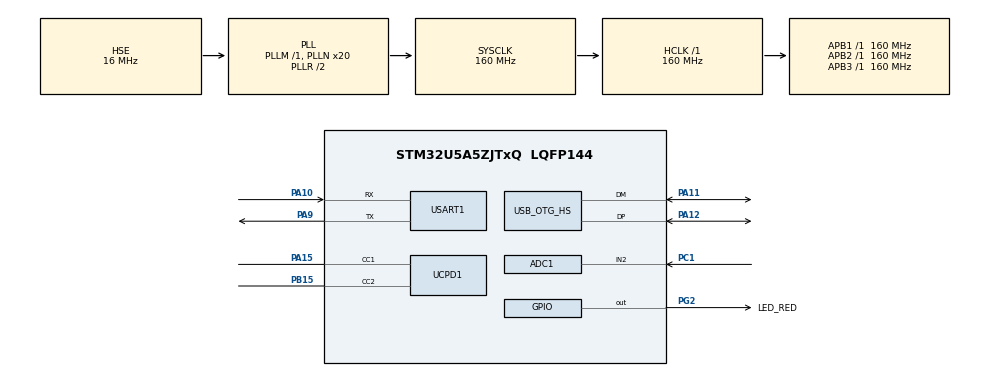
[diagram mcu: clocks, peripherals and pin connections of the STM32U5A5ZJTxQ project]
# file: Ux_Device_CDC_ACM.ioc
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ADC1.Channel-1\#ChannelRegularConversion=ADC_CHANNEL_2
ADC1.MonitoredBy-1\#ChannelRegularConversion=__NULL
ADC1.NbrOfConversionFlag=1
ADC1.OffsetNumber-1\#ChannelRegularConversion=ADC_OFFSET_NONE
ADC1.Rank-1\#ChannelRegularConversion=1
ADC1.SamplingTime-1\#ChannelRegularConversion=ADC_SAMPLETIME_5CYCLE
ADC1.master=1
CORTEX_M33_NS.userName=CORTEX_M33
GPDMA1.DIRECTION_GPDMACH0=DMA_MEMORY_TO_PERIPH
GPDMA1.DIRECTION_GPDMACH3=DMA_MEMORY_TO_PERIPH
GPDMA1.IPHANDLE_GPDMACH0-SIMPLEREQUEST_GPDMACH0=__NULL
GPDMA1.IPHANDLE_GPDMACH3-SIMPLEREQUEST_GPDMACH3=__NULL
GPDMA1.IPHANDLE_GPDMACH5-SIMPLEREQUEST_GPDMACH5=__NULL
GPDMA1.REQUEST_GPDMACH0=GPDMA1_REQUEST_USART1_TX
GPDMA1.REQUEST_GPDMACH3=GPDMA1_REQUEST_UCPD1_TX
GPDMA1.REQUEST_GPDMACH5=GPDMA1_REQUEST_UCPD1_RX
GPDMA1.SRCINC_GPDMACH0=DMA_SINC_INCREMENTED
Mcu.Family=STM32U5
Mcu.Name=STM32U5A5ZJTxQ
Mcu.Package=LQFP144
NVIC.GPDMA1_Channel0_IRQn=true\:0\:0\:false\:false\:true\:true\:true\:true\:true
NVIC.GPDMA1_Channel3_IRQn=true\:0\:0\:false\:false\:true\:true\:true\:true\:true
NVIC.GPDMA1_Channel5_IRQn=true\:0\:0\:false\:false\:true\:true\:true\:true\:true
NVIC.OTG_HS_IRQn=true\:7\:0\:true\:false\:true\:false\:true\:true\:true
NVIC.PriorityGroup=NVIC_PRIORITYGROUP_4
NVIC.TIM6_IRQn=true\:15\:0\:false\:false\:true\:false\:false\:true\:true
NVIC.TimeBase=TIM6_IRQn
NVIC.TimeBaseIP=TIM6
NVIC.UCPD1_IRQn=true\:5\:0\:true\:false\:true\:false\:true\:false\:true
NVIC.USART1_IRQn=true\:6\:0\:true\:false\:true\:false\:true\:true\:true
PA10.GPIO_PuPd=GPIO_PULLUP
PA10.GPIO_Speed=GPIO_SPEED_FREQ_HIGH
PA10.Mode=Asynchronous
PA10.Signal=USART1_RX
PA11.GPIO_Speed=GPIO_SPEED_FREQ_LOW
PA11.Mode=Internal_Phy_Device
PA11.Signal=USB_OTG_HS_DM
PA12.GPIO_Speed=GPIO_SPEED_FREQ_LOW
PA12.Mode=Internal_Phy_Device
PA12.Signal=USB_OTG_HS_DP
PA15\ (JTDI).Mode=Sink_AllSignals
PA15\ (JTDI).Signal=UCPD1_CC1
PA9.GPIO_PuPd=GPIO_PULLUP
PA9.GPIO_Speed=GPIO_SPEED_FREQ_HIGH
PA9.Mode=Asynchronous
PA9.Signal=USART1_TX
PB15.Mode=Sink_AllSignals
PB15.Signal=UCPD1_CC2
PC1.Mode=IN2-Single-Ended
PC1.Signal=ADC1_IN2
PG2.GPIO_Label=LED_RED
PG2.Signal=GPIO_Output
PH0-OSC_IN\ (PH0).Mode=HSE-External-Oscillator
PH0-OSC_IN\ (PH0).Signal=RCC_OSC_IN
PH1-OSC_OUT\ (PH1).Mode=HSE-External-Oscillator
PH1-OSC_OUT\ (PH1).Signal=RCC_OSC_OUT
PWR.PowerMode=PWR_SMPS_SUPPLY
ProjectManager.HeapSize=0x200
ProjectManager.StackSize=0x400
ProjectManager.TargetToolchain=EWARM V8.50
RCC.ADCFreq_Value=16000000
RCC.AHBFreq_Value=160000000
RCC.APB1Freq_Value=160000000
RCC.APB1TimFreq_Value=160000000
RCC.APB2Freq_Value=160000000
RCC.APB2TimFreq_Value=160000000
RCC.APB3Freq_Value=160000000
RCC.CortexFreq_Value=160000000
RCC.DACCLockSelectionVirtual=RCC_DAC1CLKSOURCE_LSI
RCC.EPOD_VALUE=16000000
RCC.HCLKFreq_Value=160000000
RCC.HSE_VALUE=16000000
RCC.HSI48_VALUE=48000000
RCC.HSI_VALUE=16000000
RCC.LSE_VALUE=32768
RCC.LSIDIV_VALUE=32000
RCC.MSIClockRange=RCC_MSIRANGE_0
RCC.MSI_VALUE=48000000
RCC.PLL1P=8
RCC.PLL2FRACN=0
RCC.PLL3FRACN=0
RCC.PLLFRACN=0
RCC.PLLN=20
RCC.PLLSourceVirtual=RCC_PLLSOURCE_HSE
RCC.SYSCLKFreq_VALUE=160000000
RCC.SYSCLKSource=RCC_SYSCLKSOURCE_PLLCLK
RCC.USBPHYCLockSelection=RCC_USBPHYCLKSOURCE_HSE
RCC.VCOOutputFreq_Value=320000000
USART1.VirtualMode-Asynchronous=VM_ASYNC
USBX.BSP.number=1
USBX.Core_System=1
USBX.MAX_POWER_IN_MILLI_AMPER=0
USBX.USBD_CDCACM_EPINCMD_ADDR=2
USBX.USBD_CDCACM_EPIN_ADDR=1
USBX.USBD_CDCACM_EPIN_HS_MPS=512
USBX.USBD_CDCACM_EPOUT_HS_MPS=512
USBX.USBD_PID=22336
USBX.USBD_PRODUCT_STRING=STM32 Virtual ComPort
USBX.USBD_SERIAL_NUMBER=CDC_ACM001
USBX.USBX_DEVICE_SYS_SIZE=4*1024
USBX.UX_DEVICE_APP_MEM_POOL_SIZE=8192
USBX.UX_DEVICE_CDC_ACM=1
USBX.UX_Device_Controller=1
USBX.UX_Device_CoreStack=1
USBX.UX_SLAVE_REQUEST_CONTROL_MAX_LENGTH=256
USBX.UX_SLAVE_REQUEST_DATA_MAX_LENGTH=512
USBX0.BSP.STBoard=false
USBX0.BSP.api=Unknown
USBX0.BSP.instance=USB_OTG_HS
USBX0.BSP.ip=USB_OTG_HS
USBX0.BSP.mode=Device_Only
USBX0.BSP.name=USBDevice
USBX0.BSP.solution=USB_OTG_HS
USB_OTG_HS.VirtualMode=Device_HS
VP_GPDMA1_VS_GPDMACH0.Mode=SIMPLEREQUEST_GPDMACH0
VP_GPDMA1_VS_GPDMACH3.Mode=SIMPLEREQUEST_GPDMACH3
VP_GPDMA1_VS_GPDMACH5.Mode=SIMPLEREQUEST_GPDMACH5
VP_ICACHE_VS_ICACHE.Mode=DirectMappedCache
VP_PWR_VS_DBSignals.Mode=DisableDeadBatterySignals
VP_PWR_VS_LPOM.Mode=PowerOptimisation
VP_PWR_VS_SECSignals.Mode=Security/Privilege
VP_SYS_VS_tim6.Mode=TIM6
VP_THREADX_VS_RTOSJjThreadXJjCoreJjDefault.Mode=Core_Default
VP_USBPD_VS_PD3TYPEC.Mode=PD3_TypeC
VP_USBPD_VS_USBPD1.Mode=USBPD_P0
VP_USBPD_VS_usbpd_tim2.Mode=TIM2
VP_USBPD_VS_usbpd_usb_cohabitation.Mode=Enable USB Support
VP_USBX_Core_System.Mode=Core_System
VP_USBX_UX\ Device\ CDC\ ACM\ Class_HS.Mode=UX_Device_class_CDC_ACM_HS
VP_USBX_UX\ Device\ Controller_HS.Mode=UX_Device_Controller_HS
VP_USBX_UX\ Device\ CoreStack_HS.Mode=UX_Device_CoreStack_HS
board=NUCLEO-U5A5ZJ-Q

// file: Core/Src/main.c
/* USER CODE BEGIN Header */
/**
  ******************************************************************************
  * @file           : main.c
  * @brief          : Main program body
  ******************************************************************************
  * @attention
  *
  * Copyright (c) 2021 STMicroelectronics.
  * All rights reserved.
  *
  * This software is licensed under terms that can be found in the LICENSE file
  * in the root directory of this software component.
  * If no LICENSE file comes with this software, it is provided AS-IS.
  *
  ******************************************************************************
  */
/* USER CODE END Header */
#include "app_threadx.h"
#include "main.h"
#include "usbpd.h"

 ADC_HandleTypeDef hadc1;

UART_HandleTypeDef huart1;
DMA_HandleTypeDef handle_GPDMA1_Channel0;

PCD_HandleTypeDef hpcd_USB_OTG_HS;

void SystemClock_Config(void);
static void SystemPower_Config(void);
static void MX_GPIO_Init(void);
static void MX_GPDMA1_Init(void);
static void MX_ICACHE_Init(void);
static void MX_UCPD1_Init(void);
static void MX_ADC1_Init(void);

int main(void)
{

  /* MCU Configuration--------------------------------------------------------*/

  /* Reset of all peripherals, Initializes the Flash interface and the Systick. */
  HAL_Init();

  /* Configure the system clock */
  SystemClock_Config();

  /* Configure the System Power */
  SystemPower_Config();

  /* Initialize all configured peripherals */
  MX_GPIO_Init();
  MX_GPDMA1_Init();
  MX_ICACHE_Init();
  MX_USART1_UART_Init();
  MX_UCPD1_Init();
  MX_ADC1_Init();
  /* Call PreOsInit function */
  USBPD_PreInitOs();

  MX_ThreadX_Init();

  /* We should never get here as control is now taken by the scheduler */

  /* Infinite loop */
  while (1)
  {

  }
}

void SystemClock_Config(void)
{
  RCC_OscInitTypeDef RCC_OscInitStruct = {0};
  RCC_ClkInitTypeDef RCC_ClkInitStruct = {0};

  /** Configure the main internal regulator output voltage
  */
  if (HAL_PWREx_ControlVoltageScaling(PWR_REGULATOR_VOLTAGE_SCALE1) != HAL_OK)
  {
    Error_Handler();
  }

  /** Initializes the CPU, AHB and APB buses clocks
  */
  RCC_OscInitStruct.OscillatorType = RCC_OSCILLATORTYPE_HSI|RCC_OSCILLATORTYPE_HSE;
  RCC_OscInitStruct.HSEState = RCC_HSE_ON;
  RCC_OscInitStruct.HSIState = RCC_HSI_ON;
  RCC_OscInitStruct.HSICalibrationValue = RCC_HSICALIBRATION_DEFAULT;
  RCC_OscInitStruct.PLL.PLLState = RCC_PLL_ON;
  RCC_OscInitStruct.PLL.PLLSource = RCC_PLLSOURCE_HSE;
  RCC_OscInitStruct.PLL.PLLMBOOST = RCC_PLLMBOOST_DIV1;
  RCC_OscInitStruct.PLL.PLLM = 1;
  RCC_OscInitStruct.PLL.PLLN = 20;
  RCC_OscInitStruct.PLL.PLLP = 8;
  RCC_OscInitStruct.PLL.PLLQ = 2;
  RCC_OscInitStruct.PLL.PLLR = 2;
  RCC_OscInitStruct.PLL.PLLRGE = RCC_PLLVCIRANGE_1;
  RCC_OscInitStruct.PLL.PLLFRACN = 0;
  if (HAL_RCC_OscConfig(&RCC_OscInitStruct) != HAL_OK)
  {
    Error_Handler();
  }

  /** Initializes the CPU, AHB and APB buses clocks
  */
  RCC_ClkInitStruct.ClockType = RCC_CLOCKTYPE_HCLK|RCC_CLOCKTYPE_SYSCLK
                              |RCC_CLOCKTYPE_PCLK1|RCC_CLOCKTYPE_PCLK2
                              |RCC_CLOCKTYPE_PCLK3;
  RCC_ClkInitStruct.SYSCLKSource = RCC_SYSCLKSOURCE_PLLCLK;
  RCC_ClkInitStruct.AHBCLKDivider = RCC_SYSCLK_DIV1;
  RCC_ClkInitStruct.APB1CLKDivider = RCC_HCLK_DIV1;
  RCC_ClkInitStruct.APB2CLKDivider = RCC_HCLK_DIV1;
  RCC_ClkInitStruct.APB3CLKDivider = RCC_HCLK_DIV1;

  if (HAL_RCC_ClockConfig(&RCC_ClkInitStruct, FLASH_LATENCY_4) != HAL_OK)
  {
    Error_Handler();
  }
}

/**
  * @brief Power Configuration
  * @retval None
  */
static void SystemPower_Config(void)
{
  HAL_PWREx_EnableVddIO2();

  /*
   * Switch to SMPS regulator instead of LDO
   */
  if (HAL_PWREx_ConfigSupply(PWR_SMPS_SUPPLY) != HAL_OK)
  {
    Error_Handler();
  }
}

static void MX_ADC1_Init(void)
{

  ADC_ChannelConfTypeDef sConfig = {0};

  /** Common config
  */
  hadc1.Instance = ADC1;
  hadc1.Init.ClockPrescaler = ADC_CLOCK_ASYNC_DIV1;
  hadc1.Init.Resolution = ADC_RESOLUTION_14B;
  hadc1.Init.GainCompensation = 0;
  hadc1.Init.DataAlign = ADC_DATAALIGN_RIGHT;
  hadc1.Init.ScanConvMode = ADC_SCAN_DISABLE;
  hadc1.Init.EOCSelection = ADC_EOC_SINGLE_CONV;
  hadc1.Init.LowPowerAutoWait = DISABLE;
  hadc1.Init.ContinuousConvMode = DISABLE;
  hadc1.Init.NbrOfConversion = 1;
  hadc1.Init.DiscontinuousConvMode = DISABLE;
  hadc1.Init.ExternalTrigConv = ADC_SOFTWARE_START;
  hadc1.Init.ExternalTrigConvEdge = ADC_EXTERNALTRIGCONVEDGE_NONE;
  hadc1.Init.DMAContinuousRequests = DISABLE;
  hadc1.Init.TriggerFrequencyMode = ADC_TRIGGER_FREQ_HIGH;
  hadc1.Init.Overrun = ADC_OVR_DATA_PRESERVED;
  hadc1.Init.LeftBitShift = ADC_LEFTBITSHIFT_NONE;
  hadc1.Init.ConversionDataManagement = ADC_CONVERSIONDATA_DR;
  hadc1.Init.OversamplingMode = DISABLE;
  if (HAL_ADC_Init(&hadc1) != HAL_OK)
  {
    Error_Handler();
  }

  /** Configure Regular Channel
  */
  sConfig.Channel = ADC_CHANNEL_2;
  sConfig.Rank = ADC_REGULAR_RANK_1;
  sConfig.SamplingTime = ADC_SAMPLETIME_5CYCLE;
  sConfig.SingleDiff = ADC_SINGLE_ENDED;
  sConfig.OffsetNumber = ADC_OFFSET_NONE;
  sConfig.Offset = 0;
  if (HAL_ADC_ConfigChannel(&hadc1, &sConfig) != HAL_OK)
  {
    Error_Handler();
  }

}

static void MX_GPDMA1_Init(void)
{

  /* Peripheral clock enable */
  __HAL_RCC_GPDMA1_CLK_ENABLE();

  /* GPDMA1 interrupt Init */
    HAL_NVIC_SetPriority(GPDMA1_Channel0_IRQn, 0, 0);
    HAL_NVIC_EnableIRQ(GPDMA1_Channel0_IRQn);
    HAL_NVIC_SetPriority(GPDMA1_Channel3_IRQn, 0, 0);
    HAL_NVIC_EnableIRQ(GPDMA1_Channel3_IRQn);
    HAL_NVIC_SetPriority(GPDMA1_Channel5_IRQn, 0, 0);
    HAL_NVIC_EnableIRQ(GPDMA1_Channel5_IRQn);

}

static void MX_ICACHE_Init(void)
{

  /** Enable instruction cache in 1-way (direct mapped cache)
  */
  if (HAL_ICACHE_ConfigAssociativityMode(ICACHE_1WAY) != HAL_OK)
  {
    Error_Handler();
  }
  if (HAL_ICACHE_Enable() != HAL_OK)
  {
    Error_Handler();
  }

}

static void MX_UCPD1_Init(void)
{

  LL_GPIO_InitTypeDef GPIO_InitStruct = {0};
  LL_DMA_InitTypeDef DMA_InitStruct = {0};

  /* Peripheral clock enable */
  LL_APB1_GRP2_EnableClock(LL_APB1_GRP2_PERIPH_UCPD1);

  LL_AHB2_GRP1_EnableClock(LL_AHB2_GRP1_PERIPH_GPIOB);
  LL_AHB2_GRP1_EnableClock(LL_AHB2_GRP1_PERIPH_GPIOA);
  /**UCPD1 GPIO Configuration
  PB15   ------> UCPD1_CC2
  PA15 (JTDI)   ------> UCPD1_CC1
  */
  GPIO_InitStruct.Pin = LL_GPIO_PIN_15;
  GPIO_InitStruct.Mode = LL_GPIO_MODE_ANALOG;
  GPIO_InitStruct.Pull = LL_GPIO_PULL_NO;
  LL_GPIO_Init(GPIOB, &GPIO_InitStruct);

  GPIO_InitStruct.Pin = LL_GPIO_PIN_15;
  GPIO_InitStruct.Mode = LL_GPIO_MODE_ANALOG;
  GPIO_InitStruct.Pull = LL_GPIO_PULL_NO;
  LL_GPIO_Init(GPIOA, &GPIO_InitStruct);

  /* UCPD1 DMA Init */

  /* GPDMA1_REQUEST_UCPD1_RX Init */
  DMA_InitStruct.SrcAddress = 0x00000000U;
  DMA_InitStruct.DestAddress = 0x00000000U;
  DMA_InitStruct.Direction = LL_DMA_DIRECTION_PERIPH_TO_MEMORY;
  DMA_InitStruct.BlkHWRequest = LL_DMA_HWREQUEST_SINGLEBURST;
  DMA_InitStruct.DataAlignment = LL_DMA_DATA_ALIGN_ZEROPADD;
  DMA_InitStruct.SrcBurstLength = 1;
  DMA_InitStruct.DestBurstLength = 1;
  DMA_InitStruct.SrcDataWidth = LL_DMA_SRC_DATAWIDTH_BYTE;
  DMA_InitStruct.DestDataWidth = LL_DMA_DEST_DATAWIDTH_BYTE;
  DMA_InitStruct.SrcIncMode = LL_DMA_SRC_FIXED;
  DMA_InitStruct.DestIncMode = LL_DMA_DEST_FIXED;
  DMA_InitStruct.Priority = LL_DMA_LOW_PRIORITY_LOW_WEIGHT;
  DMA_InitStruct.BlkDataLength = 0x00000000U;
  DMA_InitStruct.TriggerMode = LL_DMA_TRIGM_BLK_TRANSFER;
  DMA_InitStruct.TriggerPolarity = LL_DMA_TRIG_POLARITY_MASKED;
  DMA_InitStruct.TriggerSelection = 0x00000000U;
  DMA_InitStruct.Request = LL_GPDMA1_REQUEST_UCPD1_RX;
  DMA_InitStruct.TransferEventMode = LL_DMA_TCEM_BLK_TRANSFER;
  DMA_InitStruct.SrcAllocatedPort = LL_DMA_SRC_ALLOCATED_PORT0;
  DMA_InitStruct.DestAllocatedPort = LL_DMA_DEST_ALLOCATED_PORT0;
  DMA_InitStruct.LinkAllocatedPort = LL_DMA_LINK_ALLOCATED_PORT1;
  DMA_InitStruct.LinkStepMode = LL_DMA_LSM_FULL_EXECUTION;
  DMA_InitStruct.LinkedListBaseAddr = 0x00000000U;
  DMA_InitStruct.LinkedListAddrOffset = 0x00000000U;
  LL_DMA_Init(GPDMA1, LL_DMA_CHANNEL_5, &DMA_InitStruct);

  /* GPDMA1_REQUEST_UCPD1_TX Init */
  DMA_InitStruct.SrcAddress = 0x00000000U;
  DMA_InitStruct.DestAddress = 0x00000000U;
  DMA_InitStruct.Direction = LL_DMA_DIRECTION_MEMORY_TO_PERIPH;
  DMA_InitStruct.BlkHWRequest = LL_DMA_HWREQUEST_SINGLEBURST;
  DMA_InitStruct.DataAlignment = LL_DMA_DATA_ALIGN_ZEROPADD;
  DMA_InitStruct.SrcBurstLength = 1;
  DMA_InitStruct.DestBurstLength = 1;
  DMA_InitStruct.SrcDataWidth = LL_DMA_SRC_DATAWIDTH_BYTE;
  DMA_InitStruct.DestDataWidth = LL_DMA_DEST_DATAWIDTH_BYTE;
  DMA_InitStruct.SrcIncMode = LL_DMA_SRC_FIXED;
  DMA_InitStruct.DestIncMode = LL_DMA_DEST_FIXED;
  DMA_InitStruct.Priority = LL_DMA_LOW_PRIORITY_LOW_WEIGHT;
  DMA_InitStruct.BlkDataLength = 0x00000000U;
  DMA_InitStruct.TriggerMode = LL_DMA_TRIGM_BLK_TRANSFER;
  DMA_InitStruct.TriggerPolarity = LL_DMA_TRIG_POLARITY_MASKED;
  DMA_InitStruct.TriggerSelection = 0x00000000U;
  DMA_InitStruct.Request = LL_GPDMA1_REQUEST_UCPD1_TX;
  DMA_InitStruct.TransferEventMode = LL_DMA_TCEM_BLK_TRANSFER;
  DMA_InitStruct.SrcAllocatedPort = LL_DMA_SRC_ALLOCATED_PORT0;
  DMA_InitStruct.DestAllocatedPort = LL_DMA_DEST_ALLOCATED_PORT0;
  DMA_InitStruct.LinkAllocatedPort = LL_DMA_LINK_ALLOCATED_PORT1;
  DMA_InitStruct.LinkStepMode = LL_DMA_LSM_FULL_EXECUTION;
  DMA_InitStruct.LinkedListBaseAddr = 0x00000000U;
  DMA_InitStruct.LinkedListAddrOffset = 0x00000000U;
  LL_DMA_Init(GPDMA1, LL_DMA_CHANNEL_3, &DMA_InitStruct);

  /* UCPD1 interrupt Init */
  NVIC_SetPriority(UCPD1_IRQn, NVIC_EncodePriority(NVIC_GetPriorityGrouping(),5, 0));
  NVIC_EnableIRQ(UCPD1_IRQn);

}

void MX_USART1_UART_Init(void)
{

  huart1.Instance = USART1;
  huart1.Init.BaudRate = 115200;
  huart1.Init.WordLength = UART_WORDLENGTH_8B;
  huart1.Init.StopBits = UART_STOPBITS_1;
  huart1.Init.Parity = UART_PARITY_NONE;
  huart1.Init.Mode = UART_MODE_TX_RX;
  huart1.Init.HwFlowCtl = UART_HWCONTROL_NONE;
  huart1.Init.OverSampling = UART_OVERSAMPLING_16;
  huart1.Init.OneBitSampling = UART_ONE_BIT_SAMPLE_DISABLE;
  huart1.Init.ClockPrescaler = UART_PRESCALER_DIV1;
  huart1.AdvancedInit.AdvFeatureInit = UART_ADVFEATURE_NO_INIT;
  if (HAL_UART_Init(&huart1) != HAL_OK)
  {
    Error_Handler();
  }
  if (HAL_UARTEx_SetTxFifoThreshold(&huart1, UART_TXFIFO_THRESHOLD_1_8) != HAL_OK)
  {
    Error_Handler();
  }
  if (HAL_UARTEx_SetRxFifoThreshold(&huart1, UART_RXFIFO_THRESHOLD_1_8) != HAL_OK)
  {
    Error_Handler();
  }
  if (HAL_UARTEx_DisableFifoMode(&huart1) != HAL_OK)
  {
    Error_Handler();
  }

}

void MX_USB_OTG_HS_PCD_Init(void)
{

  hpcd_USB_OTG_HS.Instance = USB_OTG_HS;
  hpcd_USB_OTG_HS.Init.dev_endpoints = 9;
  hpcd_USB_OTG_HS.Init.speed = PCD_SPEED_HIGH;
  hpcd_USB_OTG_HS.Init.phy_itface = USB_OTG_HS_EMBEDDED_PHY;
  hpcd_USB_OTG_HS.Init.Sof_enable = DISABLE;
  hpcd_USB_OTG_HS.Init.low_power_enable = DISABLE;
  hpcd_USB_OTG_HS.Init.lpm_enable = DISABLE;
  hpcd_USB_OTG_HS.Init.use_dedicated_ep1 = DISABLE;
  hpcd_USB_OTG_HS.Init.vbus_sensing_enable = DISABLE;
  hpcd_USB_OTG_HS.Init.dma_enable = DISABLE;
  if (HAL_PCD_Init(&hpcd_USB_OTG_HS) != HAL_OK)
  {
    Error_Handler();
  }

}

static void MX_GPIO_Init(void)
{
  GPIO_InitTypeDef GPIO_InitStruct = {0};

  /* GPIO Ports Clock Enable */
  __HAL_RCC_GPIOH_CLK_ENABLE();
  __HAL_RCC_GPIOC_CLK_ENABLE();
  __HAL_RCC_GPIOB_CLK_ENABLE();
  __HAL_RCC_GPIOG_CLK_ENABLE();
  __HAL_RCC_GPIOA_CLK_ENABLE();

  /*Configure GPIO pin Output Level */
  HAL_GPIO_WritePin(LED_RED_GPIO_Port, LED_RED_Pin, GPIO_PIN_RESET);

  /*Configure GPIO pin : LED_RED_Pin */
  GPIO_InitStruct.Pin = LED_RED_Pin;
  GPIO_InitStruct.Mode = GPIO_MODE_OUTPUT_PP;
  GPIO_InitStruct.Pull = GPIO_NOPULL;
  GPIO_InitStruct.Speed = GPIO_SPEED_FREQ_LOW;
  HAL_GPIO_Init(LED_RED_GPIO_Port, &GPIO_InitStruct);

}

void HAL_TIM_PeriodElapsedCallback(TIM_HandleTypeDef *htim)
{
  if (htim->Instance == TIM6) {
    HAL_IncTick();
  }
}

void Error_Handler(void)
{
  /* USER CODE BEGIN Error_Handler_Debug */
  /* User can add his own implementation to report the HAL error return state */
  while (1)
  {
    HAL_GPIO_TogglePin(LED_RED_GPIO_Port, LED_RED_Pin);
    HAL_Delay(200);
  }
  /* USER CODE END Error_Handler_Debug */
}
